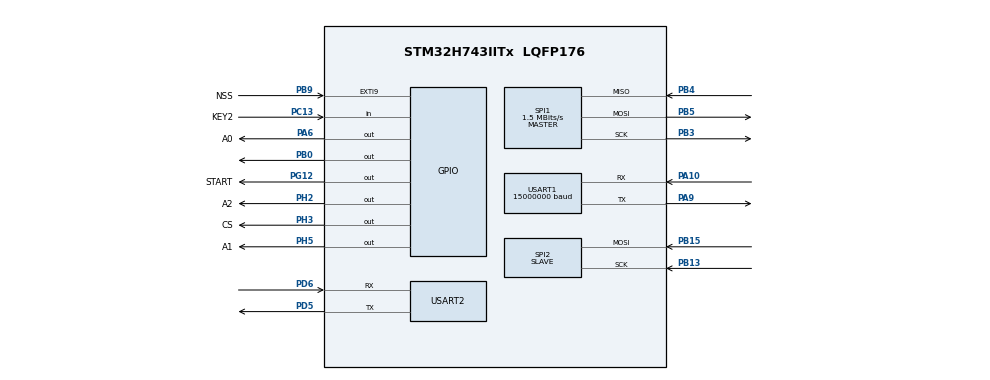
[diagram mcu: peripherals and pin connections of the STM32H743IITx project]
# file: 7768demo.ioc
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CORTEX_M7.AccessPermission_Spec=MPU_REGION_FULL_ACCESS
CORTEX_M7.BaseAddress_Spec=0x24000000
CORTEX_M7.CPU_DCache=Enabled
CORTEX_M7.CPU_ICache=Enabled
CORTEX_M7.Enable_S-Cortex_Memory_Protection_Unit_Region1_Settings_S=__NULL
CORTEX_M7.Size_Spec=MPU_REGION_SIZE_512KB
CORTEX_M7.SubRegionDisable_Spec=0x00
CORTEX_M7.default_mode_Activation=1
Dma.Request0=USART2_RX
Dma.Request1=USART2_TX
Dma.Request2=USART1_RX
Dma.Request3=USART1_TX
Dma.USART1_RX.2.Direction=DMA_PERIPH_TO_MEMORY
Dma.USART1_RX.2.EventEnable=DISABLE
Dma.USART1_RX.2.FIFOMode=DMA_FIFOMODE_DISABLE
Dma.USART1_RX.2.Instance=DMA1_Stream1
Dma.USART1_RX.2.MemDataAlignment=DMA_MDATAALIGN_BYTE
Dma.USART1_RX.2.MemInc=DMA_MINC_ENABLE
Dma.USART1_RX.2.Mode=DMA_CIRCULAR
Dma.USART1_RX.2.PeriphDataAlignment=DMA_PDATAALIGN_BYTE
Dma.USART1_RX.2.PeriphInc=DMA_PINC_DISABLE
Dma.USART1_RX.2.Polarity=HAL_DMAMUX_REQ_GEN_RISING
Dma.USART1_RX.2.Priority=DMA_PRIORITY_LOW
Dma.USART1_RX.2.RequestNumber=1
Dma.USART1_RX.2.SignalID=NONE
Dma.USART1_RX.2.SyncEnable=DISABLE
Dma.USART1_RX.2.SyncPolarity=HAL_DMAMUX_SYNC_NO_EVENT
Dma.USART1_RX.2.SyncRequestNumber=1
Dma.USART1_RX.2.SyncSignalID=NONE
Dma.USART1_TX.3.Direction=DMA_MEMORY_TO_PERIPH
Dma.USART1_TX.3.EventEnable=DISABLE
Dma.USART1_TX.3.FIFOMode=DMA_FIFOMODE_DISABLE
Dma.USART1_TX.3.Instance=DMA1_Stream2
Dma.USART1_TX.3.MemDataAlignment=DMA_MDATAALIGN_BYTE
Dma.USART1_TX.3.MemInc=DMA_MINC_ENABLE
Dma.USART1_TX.3.Mode=DMA_NORMAL
Dma.USART1_TX.3.PeriphDataAlignment=DMA_PDATAALIGN_BYTE
Dma.USART1_TX.3.PeriphInc=DMA_PINC_DISABLE
Dma.USART1_TX.3.Polarity=HAL_DMAMUX_REQ_GEN_RISING
Dma.USART1_TX.3.Priority=DMA_PRIORITY_LOW
Dma.USART1_TX.3.RequestNumber=1
Dma.USART1_TX.3.SignalID=NONE
Dma.USART1_TX.3.SyncEnable=DISABLE
Dma.USART1_TX.3.SyncPolarity=HAL_DMAMUX_SYNC_NO_EVENT
Dma.USART1_TX.3.SyncRequestNumber=1
Dma.USART1_TX.3.SyncSignalID=NONE
Dma.USART2_RX.0.Direction=DMA_PERIPH_TO_MEMORY
Dma.USART2_RX.0.EventEnable=DISABLE
Dma.USART2_RX.0.FIFOMode=DMA_FIFOMODE_DISABLE
Dma.USART2_RX.0.Instance=DMA1_Stream3
Dma.USART2_RX.0.MemDataAlignment=DMA_MDATAALIGN_BYTE
Dma.USART2_RX.0.MemInc=DMA_MINC_ENABLE
Dma.USART2_RX.0.Mode=DMA_CIRCULAR
Dma.USART2_RX.0.PeriphDataAlignment=DMA_PDATAALIGN_BYTE
Dma.USART2_RX.0.PeriphInc=DMA_PINC_DISABLE
Dma.USART2_RX.0.Polarity=HAL_DMAMUX_REQ_GEN_RISING
Dma.USART2_RX.0.Priority=DMA_PRIORITY_HIGH
Dma.USART2_RX.0.RequestNumber=1
Dma.USART2_RX.0.SignalID=NONE
Dma.USART2_RX.0.SyncEnable=DISABLE
Dma.USART2_RX.0.SyncPolarity=HAL_DMAMUX_SYNC_NO_EVENT
Dma.USART2_RX.0.SyncRequestNumber=1
Dma.USART2_RX.0.SyncSignalID=NONE
Dma.USART2_TX.1.Direction=DMA_MEMORY_TO_PERIPH
Dma.USART2_TX.1.EventEnable=DISABLE
Dma.USART2_TX.1.FIFOMode=DMA_FIFOMODE_DISABLE
Dma.USART2_TX.1.Instance=DMA1_Stream4
Dma.USART2_TX.1.MemDataAlignment=DMA_MDATAALIGN_BYTE
Dma.USART2_TX.1.MemInc=DMA_MINC_ENABLE
Dma.USART2_TX.1.Mode=DMA_NORMAL
Dma.USART2_TX.1.PeriphDataAlignment=DMA_PDATAALIGN_BYTE
Dma.USART2_TX.1.PeriphInc=DMA_PINC_DISABLE
Dma.USART2_TX.1.Polarity=HAL_DMAMUX_REQ_GEN_RISING
Dma.USART2_TX.1.Priority=DMA_PRIORITY_MEDIUM
Dma.USART2_TX.1.RequestNumber=1
Dma.USART2_TX.1.SignalID=NONE
Dma.USART2_TX.1.SyncEnable=DISABLE
Dma.USART2_TX.1.SyncPolarity=HAL_DMAMUX_SYNC_NO_EVENT
Dma.USART2_TX.1.SyncRequestNumber=1
Dma.USART2_TX.1.SyncSignalID=NONE
Mcu.Family=STM32H7
Mcu.Name=STM32H743IITx
Mcu.Package=LQFP176
NVIC.DMA1_Stream1_IRQn=true\:0\:0\:false\:false\:true\:false\:true\:true
NVIC.DMA1_Stream2_IRQn=true\:0\:0\:false\:false\:true\:false\:true\:true
NVIC.DMA1_Stream3_IRQn=true\:0\:3\:false\:false\:true\:false\:true\:true
NVIC.DMA1_Stream4_IRQn=true\:1\:0\:true\:false\:true\:false\:true\:true
NVIC.EXTI9_5_IRQn=true\:0\:0\:false\:false\:true\:true\:true\:true
NVIC.PriorityGroup=NVIC_PRIORITYGROUP_2
NVIC.SPI2_IRQn=true\:0\:0\:false\:false\:true\:true\:true\:true
NVIC.TIM6_DAC_IRQn=true\:0\:0\:false\:false\:true\:true\:true\:true
NVIC.USART1_IRQn=true\:0\:0\:false\:false\:true\:true\:true\:true
NVIC.USART2_IRQn=true\:2\:3\:true\:false\:true\:false\:true\:true
PA10.Mode=Asynchronous
PA10.Signal=USART1_RX
PA13\ (JTMS/SWDIO).Mode=Serial_Wire
PA13\ (JTMS/SWDIO).Signal=DEBUG_JTMS-SWDIO
PA14\ (JTCK/SWCLK).Mode=Serial_Wire
PA14\ (JTCK/SWCLK).Signal=DEBUG_JTCK-SWCLK
PA6.GPIO_Label=A0
PA6.Signal=GPIO_Output
PA9.Mode=Asynchronous
PA9.Signal=USART1_TX
PB0.Signal=GPIO_Output
PB13.Mode=RX_Only_Simplex_Unidirect_Slave
PB13.Signal=SPI2_SCK
PB15.Mode=RX_Only_Simplex_Unidirect_Slave
PB15.Signal=SPI2_MOSI
PB3\ (JTDO/TRACESWO).Mode=Full_Duplex_Master
PB3\ (JTDO/TRACESWO).Signal=SPI1_SCK
PB4\ (NJTRST).Mode=Full_Duplex_Master
PB4\ (NJTRST).Signal=SPI1_MISO
PB5.Mode=Full_Duplex_Master
PB5.Signal=SPI1_MOSI
PB9.GPIO_Label=NSS
PB9.Signal=GPXTI9
PC13.GPIO_Label=KEY2
PC13.Signal=GPIO_Input
PC14-OSC32_IN\ (OSC32_IN).Mode=LSE-External-Oscillator
PC14-OSC32_IN\ (OSC32_IN).Signal=RCC_OSC32_IN
PC15-OSC32_OUT\ (OSC32_OUT).Mode=LSE-External-Oscillator
PC15-OSC32_OUT\ (OSC32_OUT).Signal=RCC_OSC32_OUT
PD5.Mode=Asynchronous
PD5.Signal=USART2_TX
PD6.Mode=Asynchronous
PD6.Signal=USART2_RX
PG12.GPIO_Label=START
PG12.Signal=GPIO_Output
PH0-OSC_IN\ (PH0).Mode=HSE-External-Oscillator
PH0-OSC_IN\ (PH0).Signal=RCC_OSC_IN
PH1-OSC_OUT\ (PH1).Mode=HSE-External-Oscillator
PH1-OSC_OUT\ (PH1).Signal=RCC_OSC_OUT
PH2.GPIO_Label=A2
PH2.Signal=GPIO_Output
PH3.GPIO_Label=CS
PH3.Signal=GPIO_Output
PH5.GPIO_Label=A1
PH5.Signal=GPIO_Output
ProjectManager.HeapSize=0x200
ProjectManager.StackSize=0x400
ProjectManager.TargetToolchain=MDK-ARM V5.32
RCC.ADCFreq_Value=50390625
RCC.APB1Freq_Value=120000000
RCC.APB2Freq_Value=120000000
RCC.APB3Freq_Value=120000000
RCC.APB4Freq_Value=120000000
RCC.CortexFreq_Value=480000000
RCC.D1PPRE=RCC_APB3_DIV2
RCC.D2PPRE1=RCC_APB1_DIV2
RCC.D2PPRE2=RCC_APB2_DIV2
RCC.D3PPRE=RCC_APB4_DIV2
RCC.DIVM1=5
RCC.DIVN1=192
RCC.DIVQ1=5
RCC.HCLKFreq_Value=240000000
RCC.HPRE=RCC_HCLK_DIV2
RCC.PLL2FRACN=0
RCC.PLL3FRACN=0
RCC.PLLFRACN=0
RCC.PLLSourceVirtual=RCC_PLLSOURCE_HSE
RCC.SYSCLKFreq_VALUE=480000000
RCC.SYSCLKSource=RCC_SYSCLKSOURCE_PLLCLK
RCC.USBFreq_Value=192000000
SPI1.BaudRatePrescaler=SPI_BAUDRATEPRESCALER_128
SPI1.CalculateBaudRate=1.5 MBits/s
SPI1.DataSize=SPI_DATASIZE_8BIT
SPI1.Direction=SPI_DIRECTION_2LINES
SPI1.Mode=SPI_MODE_MASTER
SPI1.VirtualType=VM_MASTER
SPI2.CLKPolarity=SPI_POLARITY_HIGH
SPI2.DataSize=SPI_DATASIZE_8BIT
SPI2.Direction=SPI_DIRECTION_2LINES_RXONLY
SPI2.Mode=SPI_MODE_SLAVE
SPI2.VirtualType=VM_SLAVE
TIM6.Period=999
TIM6.Prescaler=239
USART1.BaudRate=15000000
USART1.OverSampling=UART_OVERSAMPLING_8
USART1.VirtualMode-Asynchronous=VM_ASYNC
USART2.VirtualMode-Asynchronous=VM_ASYNC
VP_MEMORYMAP_VS_MEMORYMAP.Mode=CurAppReg
VP_TIM6_VS_ClockSourceINT.Mode=Enable_Timer
board=custom

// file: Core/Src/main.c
/* USER CODE BEGIN Header */
/**
  ******************************************************************************
  * @file           : main.c
  * @brief          : Main program body
  ******************************************************************************
  * @attention
  *
  * Copyright (c) 2026 STMicroelectronics.
  * All rights reserved.
  *
  * This software is licensed under terms that can be found in the LICENSE file
  * in the root directory of this software component.
  * If no LICENSE file comes with this software, it is provided AS-IS.
  *
  ******************************************************************************
  */
/* USER CODE END Header */
#include "main.h"
#include "dma.h"
#include "spi.h"
#include "tim.h"
#include "usart.h"
#include "gpio.h"

/* USER CODE BEGIN Includes */
#include "stdio.h"
#include "ad7768.h"
#include "sys.h"
/* USER CODE END Includes */

void SystemClock_Config(void);
static void MPU_Config(void);

int main(void)
{

  /* MPU Configuration--------------------------------------------------------*/
  MPU_Config();

  /* Enable the CPU Cache */

  /* Enable I-Cache---------------------------------------------------------*/
  SCB_EnableICache();

  /* Enable D-Cache---------------------------------------------------------*/
  SCB_EnableDCache();

  /* MCU Configuration--------------------------------------------------------*/

  /* Reset of all peripherals, Initializes the Flash interface and the Systick. */
  HAL_Init();

  /* Configure the system clock */
  SystemClock_Config();

  /* Initialize all configured peripherals */
  MX_GPIO_Init();
  MX_DMA_Init();
  MX_SPI1_Init();
  MX_USART1_UART_Init();
  MX_USART2_UART_Init();
  MX_SPI2_Init();
  MX_TIM6_Init();

  /* Infinite loop */
  /* USER CODE BEGIN WHILE */
  UARTEx_MultiBuffer_ReceiveToIdle();
  ad7768_init();
  start();
  while (1)
  {
	  task_key();
	  ad7768_read_and_print();
//	  Send_RxData();
    /* USER CODE END WHILE */

  }
}

void SystemClock_Config(void)
{
  RCC_OscInitTypeDef RCC_OscInitStruct = {0};
  RCC_ClkInitTypeDef RCC_ClkInitStruct = {0};

  /** Supply configuration update enable
  */
  HAL_PWREx_ConfigSupply(PWR_LDO_SUPPLY);

  /** Configure the main internal regulator output voltage
  */
  __HAL_PWR_VOLTAGESCALING_CONFIG(PWR_REGULATOR_VOLTAGE_SCALE0);

  while(!__HAL_PWR_GET_FLAG(PWR_FLAG_VOSRDY)) {}

  /** Initializes the RCC Oscillators according to the specified parameters
  * in the RCC_OscInitTypeDef structure.
  */
  RCC_OscInitStruct.OscillatorType = RCC_OSCILLATORTYPE_HSE;
  RCC_OscInitStruct.HSEState = RCC_HSE_ON;
  RCC_OscInitStruct.PLL.PLLState = RCC_PLL_ON;
  RCC_OscInitStruct.PLL.PLLSource = RCC_PLLSOURCE_HSE;
  RCC_OscInitStruct.PLL.PLLM = 5;
  RCC_OscInitStruct.PLL.PLLN = 192;
  RCC_OscInitStruct.PLL.PLLP = 2;
  RCC_OscInitStruct.PLL.PLLQ = 5;
  RCC_OscInitStruct.PLL.PLLR = 2;
  RCC_OscInitStruct.PLL.PLLRGE = RCC_PLL1VCIRANGE_2;
  RCC_OscInitStruct.PLL.PLLVCOSEL = RCC_PLL1VCOWIDE;
  RCC_OscInitStruct.PLL.PLLFRACN = 0;
  if (HAL_RCC_OscConfig(&RCC_OscInitStruct) != HAL_OK)
  {
    Error_Handler();
  }

  /** Initializes the CPU, AHB and APB buses clocks
  */
  RCC_ClkInitStruct.ClockType = RCC_CLOCKTYPE_HCLK|RCC_CLOCKTYPE_SYSCLK
                              |RCC_CLOCKTYPE_PCLK1|RCC_CLOCKTYPE_PCLK2
                              |RCC_CLOCKTYPE_D3PCLK1|RCC_CLOCKTYPE_D1PCLK1;
  RCC_ClkInitStruct.SYSCLKSource = RCC_SYSCLKSOURCE_PLLCLK;
  RCC_ClkInitStruct.SYSCLKDivider = RCC_SYSCLK_DIV1;
  RCC_ClkInitStruct.AHBCLKDivider = RCC_HCLK_DIV2;
  RCC_ClkInitStruct.APB3CLKDivider = RCC_APB3_DIV2;
  RCC_ClkInitStruct.APB1CLKDivider = RCC_APB1_DIV2;
  RCC_ClkInitStruct.APB2CLKDivider = RCC_APB2_DIV2;
  RCC_ClkInitStruct.APB4CLKDivider = RCC_APB4_DIV2;

  if (HAL_RCC_ClockConfig(&RCC_ClkInitStruct, FLASH_LATENCY_4) != HAL_OK)
  {
    Error_Handler();
  }
}

 /* MPU Configuration */

void MPU_Config(void)
{
  MPU_Region_InitTypeDef MPU_InitStruct = {0};

  /* Disables the MPU */
  HAL_MPU_Disable();

  /** Initializes and configures the Region and the memory to be protected
  */
  MPU_InitStruct.Enable = MPU_REGION_ENABLE;
  MPU_InitStruct.Number = MPU_REGION_NUMBER0;
  MPU_InitStruct.BaseAddress = 0x24000000;
  MPU_InitStruct.Size = MPU_REGION_SIZE_512KB;
  MPU_InitStruct.SubRegionDisable = 0x00;
  MPU_InitStruct.TypeExtField = MPU_TEX_LEVEL0;
  MPU_InitStruct.AccessPermission = MPU_REGION_FULL_ACCESS;
  MPU_InitStruct.DisableExec = MPU_INSTRUCTION_ACCESS_DISABLE;
  MPU_InitStruct.IsShareable = MPU_ACCESS_SHAREABLE;
  MPU_InitStruct.IsCacheable = MPU_ACCESS_NOT_CACHEABLE;
  MPU_InitStruct.IsBufferable = MPU_ACCESS_NOT_BUFFERABLE;

  HAL_MPU_ConfigRegion(&MPU_InitStruct);
  /* Enables the MPU */
  HAL_MPU_Enable(MPU_PRIVILEGED_DEFAULT);

}

void Error_Handler(void)
{
  __disable_irq();
  while (1)
  {
  }
}
